AUTOSAR XML (schema 4-2-1)
standard types defined: uint8, uint16
package /Copy_VehThermMngtSrv_FD/Components
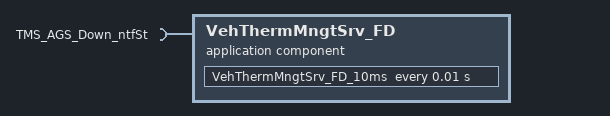
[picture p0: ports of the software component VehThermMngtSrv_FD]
  application sw component type VehThermMngtSrv_FD
    require port TMS_AGS_Down_ntfSt: nonqueued-receiver-com-spec{data-element=DataElement_ntfSt, init-value=fields=[DTE_AGSCrtSt:0, DTE_AGSCrtPosnSt:0, DTE_AGSCrtBoostMode:0, DTE_AGSCrtTorqueLevel:0, DTE_AGSCalibrationSt:0, DTE_AGSCalibrationFb:0]}, required-interface=TMS_AGS_Down_ntfSt
    behavior VehThermMngtSrv_FD_IB: data-type-mapping=[VehThermMngtSrv_FDDataTypeMappingsSet, Data_Type_Mappings], handle-termination-and-restart=NO-SUPPORT, included-data-type-set=data-type=ADT_TMS_ReturnCode
      timing event Event_VehThermMngtSrv_FD_10ms: start-on-event=VehThermMngtSrv_FD_10ms, period=0.01
      runnable VehThermMngtSrv_FD_10ms
        data-receive-point-by-arguments:
          access TMS_AGS_Down_ntfSt_DataElement_ntfSt: accessed-variable=TMS_AGS_Down_ntfSt.DataElement_ntfSt
package /Copy_VehThermMngtSrv_FD/DataTypeMappingSets
  data type mapping set Data_Type_Mappings
    data-type-maps:
      application-data-type=ADT_TMS_AGSWorkSt, implementation-data-type=IDT_TMS_AGSWorkSt
      application-data-type=ADT_TMS_AGSWorkSt, implementation-data-type=IDT_TMS_AGSWorkSt
      application-data-type=ADT_TMS_AGSWorkSt, implementation-data-type=IDT_TMS_AGSWorkSt
      application-data-type=ADT_AGSCrtSt, implementation-data-type=IDT_AGSCrtSt
      application-data-type=ADT_AGSCrtSt, implementation-data-type=IDT_AGSCrtSt
      application-data-type=ADT_AGSCrtSt, implementation-data-type=IDT_AGSCrtSt
      application-data-type=ADT_AGSCrtPosnSt, implementation-data-type=IDT_AGSCrtPosnSt
      application-data-type=ADT_AGSCrtPosnSt, implementation-data-type=IDT_AGSCrtPosnSt
      application-data-type=ADT_AGSCrtPosnSt, implementation-data-type=IDT_AGSCrtPosnSt
      application-data-type=ADT_AGSCrtBoostMode, implementation-data-type=IDT_AGSCrtBoostMode
      application-data-type=ADT_AGSCrtBoostMode, implementation-data-type=IDT_AGSCrtBoostMode
      application-data-type=ADT_AGSCrtBoostMode, implementation-data-type=IDT_AGSCrtBoostMode
      application-data-type=ADT_AGSCrtTorqueLevel, implementation-data-type=IDT_AGSCrtTorqueLevel
      application-data-type=ADT_AGSCrtTorqueLevel, implementation-data-type=IDT_AGSCrtTorqueLevel
      application-data-type=ADT_AGSCrtTorqueLevel, implementation-data-type=IDT_AGSCrtTorqueLevel
      application-data-type=ADT_AGSCalibrationSt, implementation-data-type=IDT_AGSCalibrationSt
      application-data-type=ADT_AGSCalibrationSt, implementation-data-type=IDT_AGSCalibrationSt
      application-data-type=ADT_AGSCalibrationSt, implementation-data-type=IDT_AGSCalibrationSt
      application-data-type=ADT_AGSCalibrationFb, implementation-data-type=IDT_AGSCalibrationFb
      application-data-type=ADT_AGSCalibrationFb, implementation-data-type=IDT_AGSCalibrationFb
      application-data-type=ADT_AGSCalibrationFb, implementation-data-type=IDT_AGSCalibrationFb
      application-data-type=ADT_AGSCalibrationEnable, implementation-data-type=IDT_AGSCalibrationEnable
      application-data-type=ADT_AGSCalibrationEnable, implementation-data-type=IDT_AGSCalibrationEnable
  data type mapping set VehThermMngtSrv_FDDataTypeMappingsSet
    data-type-maps:
      application-data-type=ADT_AGSCrtSt, implementation-data-type=IDT_AGSCrtSt
      application-data-type=ADT_AGSCrtSt, implementation-data-type=IDT_AGSCrtSt
      application-data-type=ADT_AGSCrtPosnSt, implementation-data-type=IDT_AGSCrtPosnSt
      application-data-type=ADT_AGSCrtPosnSt, implementation-data-type=IDT_AGSCrtPosnSt
      application-data-type=ADT_AGSCrtBoostMode, implementation-data-type=IDT_AGSCrtBoostMode
      application-data-type=ADT_AGSCrtBoostMode, implementation-data-type=IDT_AGSCrtBoostMode
      application-data-type=ADT_AGSCrtTorqueLevel, implementation-data-type=IDT_AGSCrtTorqueLevel
      application-data-type=ADT_AGSCrtTorqueLevel, implementation-data-type=IDT_AGSCrtTorqueLevel
      application-data-type=ADT_AGSCalibrationSt, implementation-data-type=IDT_AGSCalibrationSt
      application-data-type=ADT_AGSCalibrationSt, implementation-data-type=IDT_AGSCalibrationSt
      application-data-type=ADT_AGSCalibrationFb, implementation-data-type=IDT_AGSCalibrationFb
      application-data-type=ADT_AGSCalibrationFb, implementation-data-type=IDT_AGSCalibrationFb
package /Copy_VehThermMngtSrv_FD/DataTypes/ApplicationDataTypes
  7 x app type, all with category=VALUE:
    ADT_AGSCalibrationEnable: compu {phys=raw for raw 0..1}, range phys 0..1  # 主动格栅标定使能指令
    ADT_AGSCalibrationFb: compu {phys=raw for raw 0..255}, range phys 0..255  # 主动格栅标定反馈
    ADT_AGSCalibrationSt: compu {phys=raw for raw 0..255}, range phys 0..255  # 主动格栅标定状态
    ADT_AGSCrtBoostMode: compu {phys=raw for raw 0..255}, range phys 0..255  # 主动格栅当前增压模式
    ADT_AGSCrtPosnSt: compu {phys=raw*0.1 for raw 0..6553.5; unit %}, range phys 0..6553.5  # 主动格栅当前开度状态
    ADT_AGSCrtSt: compu {phys=raw for raw 0..255}, range phys 0..255  # 主动格栅当前工作状态
    ADT_AGSCrtTorqueLevel: compu {phys=raw for raw 0..255}, range phys 0..255  # 主动格栅当前扭矩等级
  application record data type ADT_TMS_AGSWorkSt: category=STRUCTURE  # 主动格栅运行状态
    6 x application record element, all with category=VALUE:
      DTE_AGSCrtSt: type=ADT_AGSCrtSt  # 主动格栅当前工作状态
      DTE_AGSCrtPosnSt: type=ADT_AGSCrtPosnSt  # 主动格栅当前开度状态
      DTE_AGSCrtBoostMode: type=ADT_AGSCrtBoostMode  # 主动格栅当前增压模式
      DTE_AGSCrtTorqueLevel: type=ADT_AGSCrtTorqueLevel  # 主动格栅当前扭矩等级
      DTE_AGSCalibrationSt: type=ADT_AGSCalibrationSt  # 主动格栅标定状态
      DTE_AGSCalibrationFb: type=ADT_AGSCalibrationFb  # 主动格栅标定反馈
package /Copy_VehThermMngtSrv_FD/DataTypes/ImplementationDataTypes
  9 x impl type:
    ADT_TMS_ReturnCode: category=VALUE, base-type=BaseTypes/uint8
    IDT_AGSCalibrationEnable: category=VALUE, base-type=SwBaseTypes/uint8  # 主动格栅标定使能指令
    IDT_AGSCalibrationFb: category=VALUE, base-type=SwBaseTypes/uint8  # 主动格栅标定反馈
    IDT_AGSCalibrationSt: category=VALUE, base-type=SwBaseTypes/uint8  # 主动格栅标定状态
    IDT_AGSCrtBoostMode: category=VALUE, base-type=SwBaseTypes/uint8  # 主动格栅当前增压模式
    IDT_AGSCrtPosnSt: category=VALUE, base-type=uint16  # 主动格栅当前开度状态
    IDT_AGSCrtSt: category=VALUE, base-type=SwBaseTypes/uint8  # 主动格栅当前工作状态
    IDT_AGSCrtTorqueLevel: category=VALUE, base-type=SwBaseTypes/uint8  # 主动格栅当前扭矩等级
    IDT_TMS_AGSWorkSt: category=STRUCTURE  # 主动格栅运行状态
      6 x element, all with category=TYPE_REFERENCE:
        DTE_AGSCrtSt: implementation-data-type=IDT_AGSCrtSt  # 主动格栅当前工作状态
        DTE_AGSCrtPosnSt: implementation-data-type=IDT_AGSCrtPosnSt  # 主动格栅当前开度状态
        DTE_AGSCrtBoostMode: implementation-data-type=IDT_AGSCrtBoostMode  # 主动格栅当前增压模式
        DTE_AGSCrtTorqueLevel: implementation-data-type=IDT_AGSCrtTorqueLevel  # 主动格栅当前扭矩等级
        DTE_AGSCalibrationSt: implementation-data-type=IDT_AGSCalibrationSt  # 主动格栅标定状态
        DTE_AGSCalibrationFb: implementation-data-type=IDT_AGSCalibrationFb  # 主动格栅标定反馈
package /Copy_VehThermMngtSrv_FD/DataTypes/Units
  unit U_AGSCrtPosnSt: display-name=%
package /Copy_VehThermMngtSrv_FD/SoftwareTypes/Interfaces
  sender receiver interface TMS_AGS_Down_ntfSt
    data DataElement_ntfSt: type=ADT_TMS_AGSWorkSt
